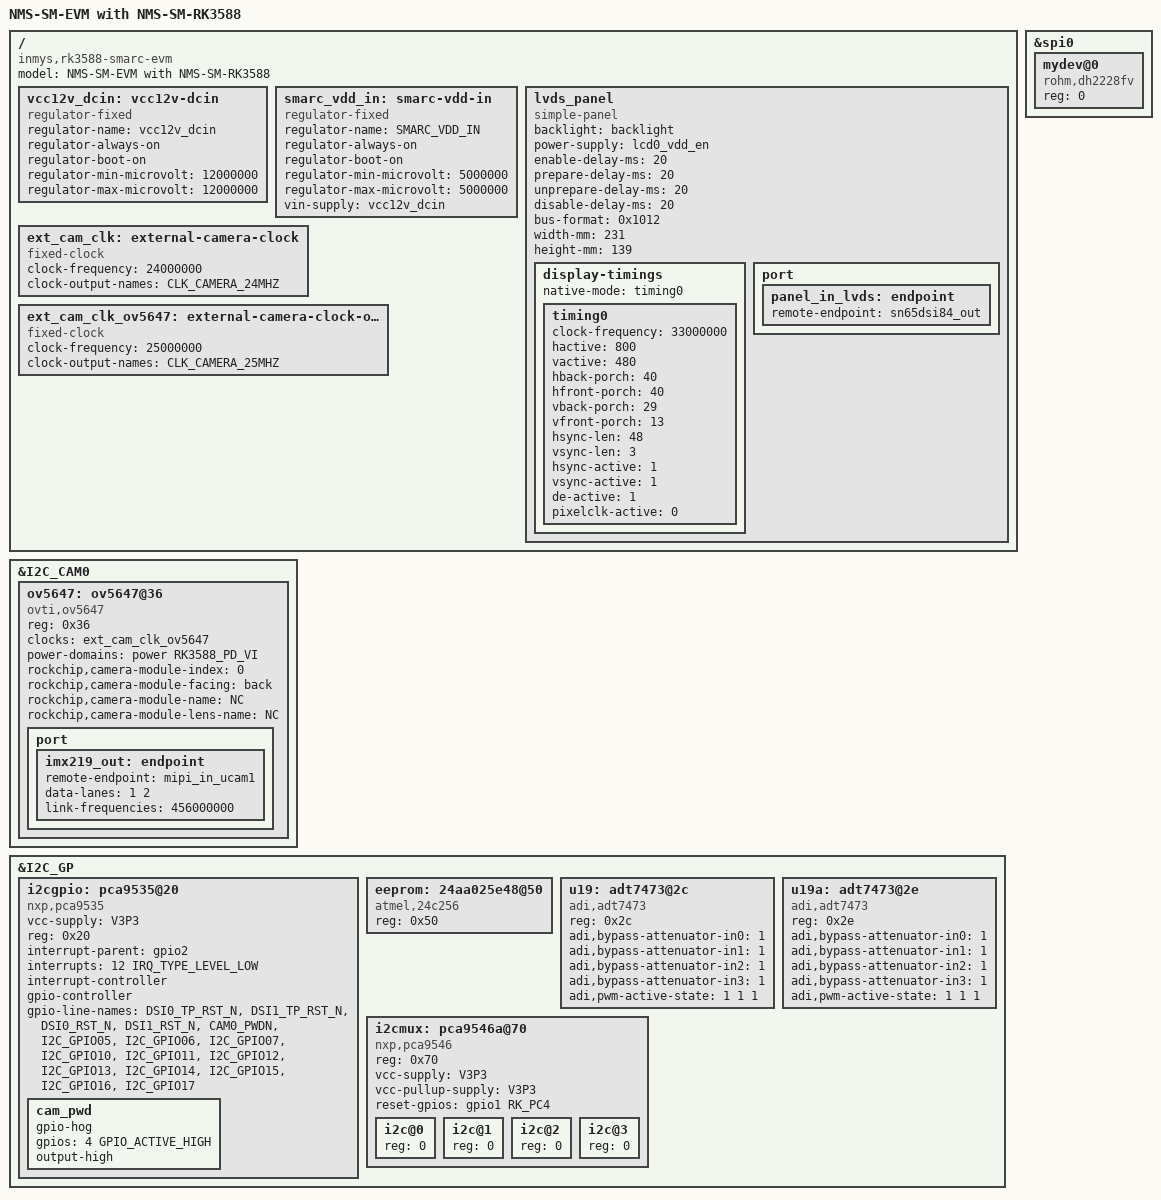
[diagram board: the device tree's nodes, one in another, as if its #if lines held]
// SPDX-License-Identifier: (GPL-2.0+ OR MIT)
/*
 * Copyright (c) 2023 Rockchip Electronics Co., Ltd.
 * Copyright (c) 2025 InMys Limited
 *
 */

/dts-v1/;

#include "rk3588-inmys-smarc-som_v2.dtsi"

/ {
	model = "NMS-SM-EVM with NMS-SM-RK3588";
	compatible = "inmys,rk3588-smarc-evm", "inmys,rk3588-smarc-som", "rockchip,rk3588";

	vcc12v_dcin: vcc12v-dcin {
		compatible = "regulator-fixed";
		regulator-name = "vcc12v_dcin";
		regulator-always-on;
		regulator-boot-on;
		regulator-min-microvolt = <12000000>;
		regulator-max-microvolt = <12000000>;
	};
	smarc_vdd_in: smarc-vdd-in {
		/* 3.0...5.25V main power input for som(from mother board) */
		compatible = "regulator-fixed";
		regulator-name = "SMARC_VDD_IN";
		regulator-always-on;
		regulator-boot-on;
		regulator-min-microvolt = <5000000>;
		regulator-max-microvolt = <5000000>;
		vin-supply = <&vcc12v_dcin>;
	};
};

#if DSI
#if DSI_TO_LVDS_BRIDGE
/* lvds panel */
/{

	lvds_panel {
		compatible = "simple-panel";
		backlight = <&backlight>;
		power-supply = <&lcd0_vdd_en>;
		enable-delay-ms = <20>;
		prepare-delay-ms = <20>;
		unprepare-delay-ms = <20>;
		disable-delay-ms = <20>;
		/* bus-format = <MEDIA_BUS_FMT_RGB666_1X7X3_SPWG>; //0x1010 */
		/* bus-format = <MEDIA_BUS_FMT_RGB888_1X7X4_SPWG>; //0x1011 */
		/* bus-format = <MEDIA_BUS_FMT_RGB888_1X7X4_JEIDA>;//0x1012  */
		bus-format = <0x1012>;
		width-mm = <231>;
		height-mm = <139>;
		display-timings {
			native-mode = <&timing0>;
			timing0: timing0 {
#if 1
				clock-frequency = <33000000>;
				hactive = <800>;
				vactive = <480>;
				hback-porch = <40>;
				hfront-porch = <40>;
				vback-porch = <29>;
				vfront-porch = <13>;
				hsync-len = <48>;
				vsync-len = <3>;
				hsync-active = <1>;
				vsync-active = <1>;
				de-active = <1>;
				pixelclk-active = <0>;
#endif
#if 0
				clock-frequency = <74250000>; //68300000
				hactive = <1280>;
				vactive = <768>;
				hback-porch = <79>;
				hfront-porch = <79>;
				vback-porch = <10>;
				vfront-porch = <10>;
				hsync-len = <1>;
				vsync-len = <1>;
				hsync-active = <1>;
				vsync-active = <1>;
				de-active = <1>;
				pixelclk-active = <1>;
#endif
			};
		};
		port {
			panel_in_lvds: endpoint {
				remote-endpoint = <&sn65dsi84_out>;
			};
		};
	};
};
#else // DSI_TO_LVDS_BRIDGE  == 0
/* dsi panel */
&dsi0 {
	panel@0 {
		reg = <0>;
		compatible = "simple-panel-dsi";
		backlight = <&backlight>;
		power-supply = <&lcd0_vdd_en>;

		enable-delay-ms = <20>;
		prepare-delay-ms = <20>;
		unprepare-delay-ms = <20>;
		disable-delay-ms = <20>;
		dsi,flags = <(MIPI_DSI_MODE_VIDEO | MIPI_DSI_MODE_VIDEO_BURST | MIPI_DSI_MODE_EOT_PACKET)>;
		//dsi,flags = <(MIPI_DSI_MODE_VIDEO | MIPI_DSI_MODE_VIDEO_BURST | MIPI_DSI_MODE_LPM | MIPI_DSI_MODE_EOT_PACKET)>;
		//dsi,flags = <(MIPI_DSI_MODE_VIDEO | MIPI_DSI_MODE_VIDEO_SYNC_PULSE | MIPI_DSI_CLOCK_NON_CONTINUOUS)>;
		//dsi,flags = <(MIPI_DSI_MODE_VIDEO | MIPI_DSI_MODE_VIDEO_SYNC_PULSE)>;
		dsi,format = <MIPI_DSI_FMT_RGB888>;
		dsi,lanes = <4>;
		width-mm = <231>;
		height-mm = <139>;
		display-timings {
			native-mode = <&timing0>;
			timing0: timing0 {
#if 0
				clock-frequency = <33000000>;
				hactive = <800>;
				vactive = <480>;
				hback-porch = <40>;
				hfront-porch = <40>;
				vback-porch = <29>;
				vfront-porch = <13>;
				hsync-len = <48>;
				vsync-len = <3>;
				hsync-active = <1>;
				vsync-active = <1>;
				de-active = <1>;
				pixelclk-active = <0>;
#endif
#if 1
				clock-frequency = <74250000>;
				hactive = <1280>;
				vactive = <768>;
				hback-porch = <79>;
				hfront-porch = <79>;
				vback-porch = <10>;
				vfront-porch = <10>;
				hsync-len = <1>;
				vsync-len = <1>;
				hsync-active = <1>;
				vsync-active = <1>;
				de-active = <1>;
				pixelclk-active = <0>;
#endif
			};
		};
		port {
			panel_in_dsi: endpoint {
				remote-endpoint = <&dsi_out_panel>;
			};
		};
	};
};
#endif // DSI_TO_LVDS_BRIDGE end
#endif // DSI end


/{
	ext_cam_clk: external-camera-clock {
		compatible = "fixed-clock";
		clock-frequency = <24000000>;
		clock-output-names = "CLK_CAMERA_24MHZ";
		#clock-cells = <0>;
	};
	ext_cam_clk_ov5647: external-camera-clock-ov5647 {
		compatible = "fixed-clock";
		clock-frequency = <25000000>;
		clock-output-names = "CLK_CAMERA_25MHZ";
		#clock-cells = <0>;
	};
};

/* SMARC: I2C_CAM0 */
&I2C_CAM0 {
	status = "okay";

#if CAM0
#if 0
	imx219: imx219@10 {
		compatible = "sony,imx219";
		reg = <0x10>;
		/*clocks = <&ext_cam_clk>;*/
		clocks = <&cru CLK_MIPI_CAMARAOUT_M1>;
		clock-names = "xvclk";

		pinctrl-names = "default";
		pinctrl-0 = <&mipim1_camera1_clk>;
		power-domains = <&power RK3588_PD_VI>;
		

		status = "okay";
		rockchip,camera-module-index = <0>;
		rockchip,camera-module-facing = "back";
		rockchip,camera-module-name = "NC";
		rockchip,camera-module-lens-name = "NC";
		port {
			imx219_out: endpoint {
				remote-endpoint = <&mipi_in_ucam1>;
				data-lanes = <1 2>;
				link-frequencies = /bits/ 64 <456000000>;
			};
		};
	};
#endif
#if 1
	ov5647: ov5647@36 {
		compatible = "ovti,ov5647";
		reg = <0x36>;

		//clocks = <&cru CLK_MIPI_CAMARAOUT_M1>;
		//clock-names = "CLK_CAMERA_25MHZ";
		//pinctrl-names = "default";
		//pinctrl-0 = <&mipim1_camera1_clk>;
		clocks = <&ext_cam_clk_ov5647>;

		// pwdn-gpios = <&i2cgpio 4 GPIO_ACTIVE_HIGH>; // I2C_GPIO04
		power-domains = <&power RK3588_PD_VI>;

		rockchip,camera-module-index = <0>;
		rockchip,camera-module-facing = "back";
		rockchip,camera-module-name = "NC";
		rockchip,camera-module-lens-name = "NC";
		port {
			imx219_out: endpoint {
				remote-endpoint = <&mipi_in_ucam1>;
				data-lanes = <1 2>;
				link-frequencies = /bits/ 64 <456000000>;
			};
		};

	};
#endif
#endif // CAM0 end
};


/* SMARC: I2C_GP */
&I2C_GP {
	i2cgpio: pca9535@20 {
		compatible = "nxp,pca9535";
		vcc-supply = <&V3P3>;
		reg = <0x20>;

		/* I2C_INT -> P111 (SMARTC  GPIO.3) -> gpio2_b4 */
		interrupt-parent = <&gpio2>;
		interrupts = <12 IRQ_TYPE_LEVEL_LOW>;
		interrupt-controller;
		#interrupt-cells = <2>;

		gpio-controller;
		#gpio-cells = <2>;
		gpio-line-names =
			"DSI0_TP_RST_N","DSI1_TP_RST_N","DSI0_RST_N","DSI1_RST_N","CAM0_PWDN","I2C_GPIO05","I2C_GPIO06","I2C_GPIO07",
			"I2C_GPIO10","I2C_GPIO11","I2C_GPIO12","I2C_GPIO13","I2C_GPIO14","I2C_GPIO15","I2C_GPIO16","I2C_GPIO17";
		cam_pwd {
		        gpio-hog;
		        gpios = <4 GPIO_ACTIVE_HIGH>;
		        output-high;
		};
	};
	eeprom: 24aa025e48@50{
		compatible = "atmel,24c256";
		reg = <0x50>;
	};
	/* one of: 0x2c or 0x2e on board */
        /* fan control */
	u19: adt7473@2c {
		compatible = "adi,adt7473";
		reg = <0x2c>;
		adi,bypass-attenuator-in0 = <1>;
		adi,bypass-attenuator-in1 = <1>;
		adi,bypass-attenuator-in2 = <1>;
		adi,bypass-attenuator-in3 = <1>;
		adi,pwm-active-state = <1 1 1>;
	};
        /* fan control2*/
	u19a: adt7473@2e {
		compatible = "adi,adt7473";
		reg = <0x2e>;
		adi,bypass-attenuator-in0 = <1>;
		adi,bypass-attenuator-in1 = <1>;
		adi,bypass-attenuator-in2 = <1>;
		adi,bypass-attenuator-in3 = <1>;
		adi,pwm-active-state = <1 1 1>;
	};

	i2cmux: pca9546a@70 {
		compatible = "nxp,pca9546";
		reg = <0x70>;
		#address-cells = <1>;
		#size-cells = <0>;
		vcc-supply = <&V3P3>;
		vcc-pullup-supply = <&V3P3>;
 
		/* gpio1_c4 -> P108 (SMARC GPIO.0) -> I2C_MUX_RST */
		reset-gpios = <&gpio1 RK_PC4 GPIO_ACTIVE_HIGH>;
		
		i2c@0 { /*I2C_DSI1 -> to X25*/
			reg = <0>;
			#address-cells = <1>; 
			#size-cells = <0>;
		};
		i2c@1 { /*I2C_DSI0 -> to X24*/
			reg = <0>;
			#address-cells = <1>; 
			#size-cells = <0>;
		};
		i2c@2 { /*I2C_GP_A -> to X32*/
			reg = <0>;
			#address-cells = <1>; 
			#size-cells = <0>;
		};
		i2c@3 { /*I2C_MPCI -> to minipcie connector*/
			reg = <0>;
			#address-cells = <1>; 
			#size-cells = <0>;
		};
	};
};

&spi0 {
	status = "okay";
	mydev@0 {
		reg = <0>;
		compatible = "rohm,dh2228fv";
	};
};

#if 0
&u19a{
	fan: cooling-device {
		compatible = "pwm-fan";
		#cooling-cells = <2>;
	};
};
&soc_thermal{
	trips {
		cpu_hot: cpu_hot {
			temperature = <45000>;
			hysteresis = <2000>;
			type = "active";
		};
	};
	cooling-maps {
		map4 {
			trip = <&cpu_hot>;
			cooling-device = <&fan THERMAL_NO_LIMIT THERMAL_NO_LIMIT>;
		};
	};
};
#endif
